# AC78xx register map
Vendor: AutoChips; Series: AC78xx; File version: 1.0
ARM 32-bit Cortex-M3 Microcontroller based device, CPU clock up to 100 MHz.
CPU: CM3 r2p1, little endian, MPU, no FPU, 3 interrupt priority bits
Registers are 32-bit, read-write, no defined reset value unless marked. A register's access mark holds for its fields unless they carry their own. Offsets are from the block's base; lines under a group give offsets from that group; [hi:lo] are bit positions; {n}, {i} and the like mark numbered series; 'fields as' and 'values as' point back to an identical list; <NAME> marks a mode.

## Memory map
0x20080000 GPIOA size 0x30 — General Purpose Input/Output
0x20080030 GPIOB size 0x30
0x20080060 GPIOC size 0x30
0x20080090 GPIOD size 0x30
0x200800C0 GPIOE size 0x30
0x20080140 PMUX size 0x4 — PinMux Function
0x20080160 EXTI size 0x18 — External Interrupt
0x40003000 ADC size 0x50 — Analog to Digital Convert Module
0x40005000 ACMP0 size 0x30 — Analog comparator
0x40005030 ACMP1 size 0x10 — Analog comparator
0x40007000 LIN0 size 0x84 — LIN Interface
0x400078A0 CAN1 size 0x2C
0x40007CA0 CAN2 size 0x2C
0x40008400 RTC size 0x14 — Real-time counter
0x4000B000 WDOG size 0x14 — Watchdog timer
0x4000C000 SPI1 size 0x18 — Serial Peripheral Interface
0x4000D000 SPI2 size 0x18 — Serial Peripheral Interface
0x4000E000 I2C1 size 0x44 — Inter-Integrated Circuit
0x4000F000 I2C2 size 0x44 — Inter-Integrated Circuit
0x40011000 TIMER size 0x100 — Timer Setting
{0x40011100+0x10*n} TIMER{n} size 0x10 (n=0..7) — Timer{n} Function
0x40012000 DMA0_TOP_RST size 0x4 — DMA0 All Channnels Share The Registers
0x40012040 DMA1 size 0x30 — DMA channel 1
{0x40012000+0x40*n} DMA{n} size 0x30 (n=2..12)
0x40013000 PWM0 size 0xA0 — Pulse Width Management Module
0x40014000 PWM1 size 0xA0 — Pulse Width Management Module
0x40015000 PWM2 size 0xA0 — Pulse Width Management Module
0x40016000 CTU size 0x10 — Connect Module Unit
0x40017000 PWDT size 0x12 — Pulse Width Detection Timer
0x40018000 UART1 size 0x60
0x40019000 UART2 size 0x60
0x4001A000 UART3 size 0x60
0x4001B000 UART4 size 0x60
0x4001C000 UART5 size 0x60
0x4001D000 UART6 size 0x60
0x4001E000 PWM3 size 0xA0 — Pulse Width Management Module

## Interrupts
0 PWDT
1 UART1
2 UART2
3 UART3
4 UART4
5 UART5
6 UART6
7 EXTI0 (EXTI) — GPIOx PIN0 external interrupt
8 EXTI1 (EXTI) — GPIOx PIN1 external interrupt
9 EXTI2 (EXTI) — GPIOx PIN2 external interrupt
10 EXTI3 (EXTI) — GPIOx PIN3 external interrupt
11 EXTI4 (EXTI) — GPIOx PIN4 external interrupt
12 EXTI5_9 (EXTI) — GPIOx PIN5~9 external interrupt
13 SPI1
14 SPI2
15 I2C1
16 I2C2
{n+16} DMA{n} (n=1..12) — DMA0 channel {n} interrupt
29 TIMER0
30 TIMER1
32 RTC
33 WDOG
34 PWM0
35 PWM1
36 PWM2
38 LIN0
39 EXTI10_15 (EXTI) — GPIOx PIN10~15 external interrupt
42 CAN1
43 CAN2
44 ADC
45 ACMP0_ (ACMP0)
46 ACMP1_ (ACMP1)
47 TIMER2
48 TIMER3
49 TIMER4
50 TIMER5
51 TIMER6
52 TIMER7
53 PWM3

## PWDT — Pulse Width Detection Timer
Base 0x40017000; register names take the prefix PWDT_
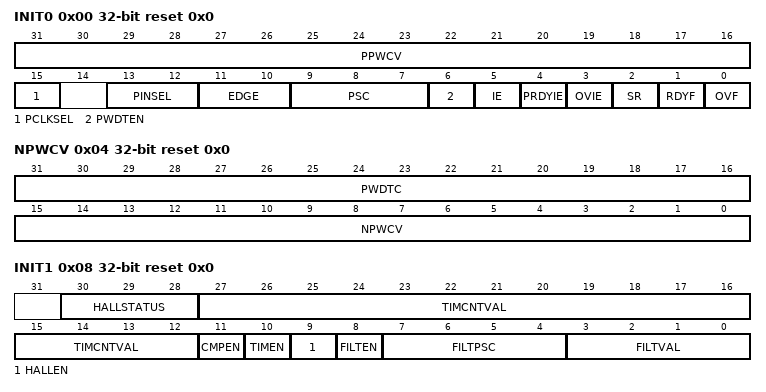
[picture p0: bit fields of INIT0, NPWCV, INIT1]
0x00 INIT0 reset 0x0 — PWDT Initialize Register 0
  [31:16] PPWCV ro — Positive Pulse Width Count Value
  [15] PCLKSEL — PWDT Clock Source Selection
    0=Bus clock is selected as the clock source of PWDT counter; 1=Alternative clock is selected as the clock source of PWDT counter
  [13:12] PINSEL — PWDT Pulse Inputs Selection
    0=PWDTIN[0] is enabled; 1=PWDTIN[1] is enabled; 2=PWDTIN[2] enabled; 3=PWDTIN[3] enabled
  [11:10] EDGE — PWDT Input Edge Sensitivity
    0=The first falling-edge starts the pulse width measurement, and on all the subsequent falling edges, the pulse width is captured; 1=The first rising edge starts the pulse width measurement, and on all the subsequent rising and falling edges, the pulse width is captured; 2=The first falling edge starts the pulse width measurement, and on all the subsequent rising and falling edges, the pulse width is captured; 3=The first-rising edge starts the pulse width measurement, and on all the subsequent rising edges, the pulse width is captured
  [9:7] PSC — PWDT Clock Prescaler (CLKPRE) Setting
    0=Clock divided by 1; 1=Clock divided by 2; 2=Clock divided by 4; 3=Clock divided by 8; 4=Clock divided by 16; 5=Clock divided by 32; 6=Clock divided by 64; 7=Clock divided by 128
  [6] PWDTEN — PWDT Module Enable
    0=The PWDT is disabled; 1=The PWDT is enabled
  [5] IE — PWDT Module Interrupt Enable
    0=Disables the PWDT to generate interrupt; 1=Enables the PWDT to generate interrupt
  [4] PRDYIE — PWDT Pulse Width Data Ready Interrupt Enable
    0=Disable PWDT to generate interrupt when PWDTRDY is set; 1=Enable PWDT to generate interrupt when PWDTRDY is set
  [3] OVIE — PWDT Counter Overflow Interrupt Enable
    0=Disable PWDT to generate interrupt when PWDTOV is set; 1=Enable PWDT to generate interrupt when PWDTOV is set
  [2] SR wo — PWDT Soft Reset Register
    0=No action taken; 1=Writing 1 to this field will perform soft reset to PWDT
  [1] RDYF — PWDT Pulse Width Valid Flag
    0=PWDT pulse width register(s) is not up-to-date; 1=PWDT pulse width register(s) has been updated
  [0] OVF — PWDT Counter Overflow flag
    0=PWDT counter no overflow; 1=PWDT counter runs from 0xFFFF to 0x0000
0x04 NPWCV ro reset 0x0 — Negative Pulse Width Count Value
  [31:16] PWDTC — PWDT Counter. It is suggested to use half-word (16-bit) or word (32-bit) to read out this value.
  [15:0] NPWCV — Negative Pulse Width. It is suggested to use half-word (16-bit) or word (32-bit) to read out this value.
0x08 INIT1 reset 0x0 — Pulse Width Detection Timer Initialize Register 1
  [30:28] HALLSTATUS ro — HALL Sensor C Status Value
  [27:12] TIMCNTVAL — PWDT Timer Load Value
  [11] CMPEN — PWDT Compare Mode Enable Bit
    0=enable the pwt_in0 ~ pwt_in2 derived from acmp0_pwt_a ~ acmp0_pwt_c external; 1=enable the pwt_in0 ~ pwt_in2 derived from acmp0_pwt_a ~ acmp0_pwt_c internally
  [10] TIMEN — PWDT Timer Function Enable Bit
    0=PWDT Timer Function Disable; 1=PWDT Timer Function Enable 
  [9] HALLEN — Hall Sensor Signal Detect function Enable Bit
    0=Hall Sensor Signal Detect function Disable; 1=Hall Sensor Signal Detect function Enable
  [8] FILTEN — PWDT input filter function Enable Bit
    0=PWDT input filter function is disable; 1=PWDT input filter function is enable
  [7:4] FILTPSC — PWDT input filter function Enable Bit
  [3:0] FILTVAL — PWDT filter Value

## Licence text in the file
ARM Limited (ARM) is supplying this software for use with Cortex-M processor based microcontroller, but can be equally used for other suitable processor architectures. This file can be freely distributed. Modifications to this file shall be clearly marked. . THIS SOFTWARE IS PROVIDED "AS IS". NO WARRANTIES, WHETHER EXPRESS, IMPLIED. OR STATUTORY, INCLUDING, BUT NOT LIMITED TO, IMPLIED WARRANTIES OF. MERCHANTABILITY AND FITNESS FOR A PARTICULAR PURPOSE APPLY TO THIS SOFTWARE. ARM SHALL NOT, IN ANY CIRCUMSTANCES, BE LIABLE FOR SPECIAL, INCIDENTAL, OR. CONSEQUENTIAL DAMAGES, FOR ANY REASON WHATSOEVER.

## Notices in the file
Copyright (C) 2012-2014 ARM Limited. All rights reserved.
Purpose: System Viewer Description (SVD) Example (Schema Version 1.1)
This is a description of a none-existent and incomplete device
for demonstration purposes only.
Redistribution and use in source and binary forms, with or without
modification, are permitted provided that the following conditions are met:
- Redistributions of source code must retain the above copyright
notice, this list of conditions and the following disclaimer.
- Redistributions in binary form must reproduce the above copyright
notice, this list of conditions and the following disclaimer in the
documentation and/or other materials provided with the distribution.
- Neither the name of ARM nor the names of its contributors may be used
to endorse or promote products derived from this software without
specific prior written permission.
THIS SOFTWARE IS PROVIDED BY THE COPYRIGHT HOLDERS AND CONTRIBUTORS "AS IS"
AND ANY EXPRESS OR IMPLIED WARRANTIES, INCLUDING, BUT NOT LIMITED TO, THE
ARE DISCLAIMED. IN NO EVENT SHALL COPYRIGHT HOLDERS AND CONTRIBUTORS BE
LIABLE FOR ANY DIRECT, INDIRECT, INCIDENTAL, SPECIAL, EXEMPLARY, OR
CONSEQUENTIAL DAMAGES (INCLUDING, BUT NOT LIMITED TO, PROCUREMENT OF
SUBSTITUTE GOODS OR SERVICES; LOSS OF USE, DATA, OR PROFITS; OR BUSINESS
INTERRUPTION) HOWEVER CAUSED AND ON ANY THEORY OF LIABILITY, WHETHER IN
CONTRACT, STRICT LIABILITY, OR TORT (INCLUDING NEGLIGENCE OR OTHERWISE)
ARISING IN ANY WAY OUT OF THE USE OF THIS SOFTWARE, EVEN IF ADVISED OF THE
POSSIBILITY OF SUCH DAMAGE.
